# aon_timer: IP-XACT component
VLNV tenstorrent.com:ocah:aon_timer:1.0

## Address spaces and blocks
aon_timer_mmap.aon_timer: base 'h0, range 'h38, width 32

## Registers
Registers are 32-bit, read-write, reset 0x0 unless marked. A register's access mark holds for its fields unless they carry their own. Offsets are from the block's base; lines under a group give offsets from that group; [hi:lo] are bit positions; {n}, {i} and the like mark numbered series; 'fields as' and 'values as' point back to an identical list; <NAME> marks a mode.

## aon_timer_mmap.aon_timer — Wakeup and watchdog timers running on a low-power, always-on clock
Base 0x00000000
0x00 ALERT_TEST wo
  [0] fatal_fault — Write 1 to trigger one alert event of this kind.
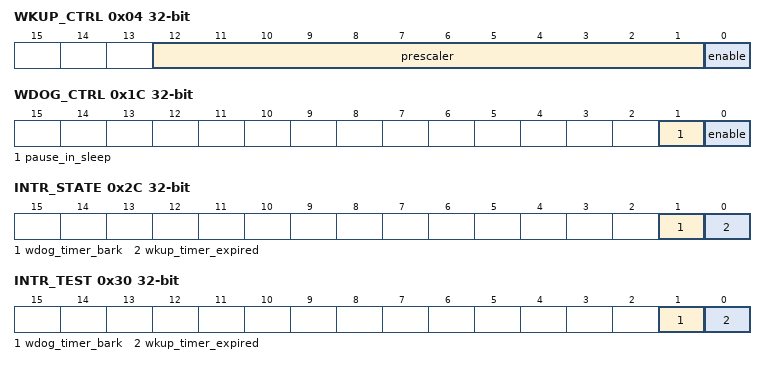
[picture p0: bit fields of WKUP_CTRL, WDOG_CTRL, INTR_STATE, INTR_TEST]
0x04 WKUP_CTRL
  [12:1] prescaler — Pre-scaler value for wakeup timer count
  [0] enable — When set to 1, the wakeup timer will count
0x08 WKUP_THOLD_HI
  [31:0] threshold_hi — The count at which a wakeup interrupt should be generated, top 32 bits.
0x0C WKUP_THOLD_LO
  [31:0] threshold_lo — The count at which a wakeup interrupt should be generated, bottom 32 bits.
0x10 WKUP_COUNT_HI
  [31:0] count_hi — The current wakeup counter value, top 32 bits.
0x14 WKUP_COUNT_LO
  [31:0] count_lo — The current wakeup counter value, bottom 32 bits.
0x18 WDOG_REGWEN reset 0x1
  [0] regwen write-0-clears — Once cleared, the watchdog configuration will be locked until the next reset.
0x1C WDOG_CTRL
  [1] pause_in_sleep — When set to 1, the watchdog timer will not count during sleep.
  [0] enable — When set to 1, the watchdog timer will count.
0x20 WDOG_BARK_THOLD
  [31:0] threshold — The count at which a watchdog bark interrupt should be generated.
0x24 WDOG_BITE_THOLD
  [31:0] threshold — The count at which a watchdog bite reset should be generated.
0x28 WDOG_COUNT
  [31:0] count — The current watchdog counter value.
0x2C INTR_STATE
  [1] wdog_timer_bark write-1-clears — Raised if the watchdog timer has hit the bark threshold.
  [0] wkup_timer_expired write-1-clears — Raised if the wakeup timer has hit the specified threshold.
0x30 INTR_TEST wo reset not defined
  [1] wdog_timer_bark — Write 1 to force wdog_timer_bark interrupt.
  [0] wkup_timer_expired — Write 1 to force wkup_timer_expired interrupt.
0x34 WKUP_CAUSE
  [0] cause write-0-clears — AON timer requested wakeup, write 0 to clear.

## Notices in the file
SPDX-License-Identifier: Apache-2.0
SPDX-FileCopyrightText: 2026 Tenstorrent USA, Inc.
